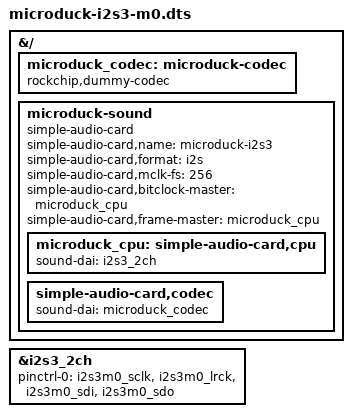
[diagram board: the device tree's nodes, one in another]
/dts-v1/;
/plugin/;

&{/} {
    /*
     * The MAX98357A is an I2S amp with no I2C control interface. This board
     * straps SD_MODE high, so Linux cannot mute it; the dummy DAI only gives
     * ALSA a link to the I2S controller. If SD_MODE is later routed to a GPIO,
     * describe the amp with maxim,max98357a and sdmode-gpios instead.
     */
    microduck_codec: microduck-codec {
        compatible = "rockchip,dummy-codec";
        #sound-dai-cells = <0>;
    };

    microduck-sound {
        compatible = "simple-audio-card";
        simple-audio-card,name = "microduck-i2s3";
        simple-audio-card,format = "i2s";
        simple-audio-card,mclk-fs = <256>;
        simple-audio-card,bitclock-master = <&microduck_cpu>;
        simple-audio-card,frame-master = <&microduck_cpu>;

        microduck_cpu: simple-audio-card,cpu {
            sound-dai = <&i2s3_2ch>;
        };

        simple-audio-card,codec {
            sound-dai = <&microduck_codec>;
        };
    };
};

&i2s3_2ch {
    pinctrl-names = "default";
    pinctrl-0 = <&i2s3m0_sclk &i2s3m0_lrck &i2s3m0_sdi &i2s3m0_sdo>;
    status = "okay";
};
